# AE612FA0E5597BS0_CM55_HP_View register map
Vendor: Alif Semiconductor; Series: E6; File version: 1.0
CPU: CM55 r1p0, selectable endian, MPU, FPU, double-precision FPU, DSP, VTOR, 8 interrupt priority bits, 1 SAU regions
Registers are 32-bit, read-write, reset 0x0 unless marked. A register's access mark holds for its fields unless they carry their own. Offsets are from the block's base; [hi:lo] are bit positions; {n}, {i} and the like mark numbered series.

## LPSPI0
Base 0x43000000
Same registers: LPSPI1 0x43004000
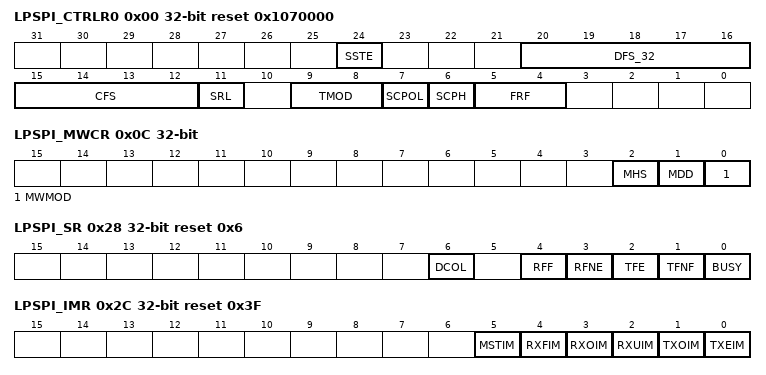
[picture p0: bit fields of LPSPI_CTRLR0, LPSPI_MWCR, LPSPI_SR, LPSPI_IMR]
0x00 LPSPI_CTRLR0 reset 0x1070000 — Control Register 0
  [24] SSTE — Slave Select Toggle Enable. While operating in LPSPI mode with clock phase (SCPH) set to 0x0, this bit controls the behavior of the slave select line between data frames.
    0=The slave select line will stay low and LPSPI_SCLK will run continuously for the duration of the transfer; 1=The slave select line will toggle between consecutive data frames, with the serial clock (LPSPI_SCLK) being held to its default value while the slave select line is high
  [20:16] DFS_32 — Data Frame Size in 32-bit transfer mode. Selects the data frame size in 32-bit transfer mode. When the data frame size is programmed to be less than 32 bits, the receive data is automatically right-justified by the receive logic, with the upper bits of the receive FIFO zero-padded. User must right-justify transmit data before writing into the transmit FIFO. The transmit logic ignores the upper unused bits when transmitting the data.
    {v}={v+1:02}-bit serial data transfer (v=3..31)
  [15:12] CFS — Control Frame Size. Selects the length of the control word for the Microwire frame format.
    {v}={v+1:02}-bit Control Word (v=0..15)
  [11] SRL — Shift Register Loop. Used for testing purposes only. When internally active, connects the transmit shift register output to the receive shift register input. Can be used in both serial slave and serial master mode.
    0=Normal Mode Operation; 1=Test Mode Operation
  [9:8] TMOD — Transfer Mode. Selects the mode of transfer for serial communication. This field does not affect the transfer duplicity. Only indicates whether the receive or transmit data are valid. In Transmit Only mode, data received from the external device is not valid and is not stored in the receive FIFO memory; it is overwritten on the next transfer. In Receive Only mode, transmitted data are not valid. After the first write to the transmit FIFO, the same word is retransmitted for the duration of the transfer. In Transmit and Receive mode, both transmit and receive data are valid. The transfer continues until the transmit FIFO is empty. Data received from the external device are stored into the receive FIFO memory, where it can be accessed by the host processor. In EEPROM-read mode, receive data is not valid while control data is being transmitted. When all control data is sent to the EEPROM, receive data becomes valid and transmit data becomes invalid. All data in the transmit FIFO is considered control data in this mode. This transfer mode is only valid when the LPSPI is programmed as master device.
    0=Transmit and Receive; 1=Transmit Only mode; 2=Receive Only mode; 3=EEPROM Read mode
  [7] SCPOL — Serial Clock Polarity. Valid when the Frame Format (FRF) bit is set to Motorola SPI. Used to select the polarity of the inactive serial clock, which is held inactive when the LPSPI master is not actively transferring data on the serial bus.
    0=Inactive state of serial clock is low; 1=Inactive state of serial clock is high
  [6] SCPH — Serial Clock Phase. Valid when the FRF bit is set to Motorola SPI. The serial clock phase selects the relationship of the serial clock with the slave select signal. When SCPH = 0, data are captured on the first edge of the serial clock. When SCPH = 1, the serial clock starts toggling one cycle after the slave select line is activated, and data are captured on the second edge of the serial clock.
    0=Serial clock toggles in middle of first bit; 1=Serial clock toggles at start of first bit
  [5:4] FRF — Frame Format. Selects which serial protocol transfers the data.
    0=Motorola SPI frame format; 1=Texas Instruments SSP frame format; 2=National Semiconductors Microwire frame format
0x04 LPSPI_CTRLR1 — Control Register 1
  [15:0] NDF — Number of Data Frames. When the LPSPI_CTRLR0[TMOD] = 0x2 or LPSPI_CTRLR0[TMOD] = 0x3, this bit field sets the number of data frames to be continuously received by the LPSPI. The LPSPI continues to receive serial data until the number of data frames received is equal to this register value plus 1, which enables the user to receive up to 64KB of data in a continuous transfer. When the SPI is programmed as a serial slave, the transfer continues for as long as the slave is selected. Therefore, this bit field serves no purpose and is not present when the SPI is programmed as a serial slave.
0x08 LPSPI_ENR — LPSPI Enable Register
  [0] SPI_EN — LPSPI Enable. Enables and disables all LPSPI operations. When disabled, all serial transfers are halted immediately. Transmit and receive FIFO buffers are cleared when the device is disabled. It is impossible to program some of the LPSPI control registers when enabled. When disabled, the LPSPI sleep output is set (after delay) to inform the system that it is safe to remove the LPSPI_CLK, thus saving power consumption in the system.
    0=Disables LPSPI; 1=Enables LPSPI
0x0C LPSPI_MWCR — Microwire Control Register
  [2] MHS — Microwire Handshaking. Relevant only when the LPSPI is programmed as a serial master device. When configured as a serial slave, this bit has no functionality. Used to enable and disable the busy/ready handshaking interface for the Microwire protocol. When enabled, the LPSPI checks for a READY status from the target slave, after the transfer of the last data/control bit, before clearing the BUSY status in the LPSPI_SR[BUSY] bit.
    0=Handshaking interface is disabled; 1=Handshaking interface is enabled
  [1] MDD — Microwire Control. Defines the direction of the data word when the Microwire serial protocol is used. When this bit is set to 0, the data word is received by the LPSPI module from the external serial device. When this bit is set to 1, the data word is transmitted from the LPSPI module to the external serial device.
    0=LPSPI receives data; 1=LPSPI transmits data
  [0] MWMOD — Microwire Transfer Mode. Defines whether the Microwire transfer is sequential or non-sequential. When sequential mode is used, only one control word is needed to transmit or receive a block of data words. When non-sequential mode is used, there must be a control word for each data word that is transmitted or received.
    0=Non-Sequential Transfer; 1=Sequential Transfer
0x10 LPSPI_SER reset 0x1 — Slave Enable Register
  [3:0] SER — Slave Select Enable Flag. Each bit in this bit field corresponds to a slave select line from the LPSPI master. When a bit in this bit field is set to 0x1, the corresponding slave select line from the master is activated when a serial transfer begins. It should be noted that setting or clearing bits in this bit field have no effect on the corresponding slave select outputs until a transfer is started. Before beginning a transfer, user should enable the bit in this field that corresponds to the slave device with which the master wants to communicate. When not operating in broadcast mode, only one bit in this field should be set.
    0=Not Selected; 1=Selected
0x14 LPSPI_BAUDR — Baud Rate Select Register
  [15:0] SCKDV — LPSPI Clock Divider. This field contains the MSB 15 bits of the 16-bit LPSPI_CLK divider value. The LSB for LPSPI_CLK divider is always set to 0 and is unaffected by a write operation, which ensures the divider is always set to an even value. If this field is set to all 0s, the serial output clock (LPSPI_SCLK) is disabled. The frequency of the LPSPI_SCLK is derived from the following equation: FLPSPI_SCLK = FLPSPI_CLK/SCKDV Where SCKDV is any even value between 2 and 65534. For example, for FLPSPI_CLK = 3.6864 MHz and SCKDV = 1b'1: SCKDV = 2 and FLPSPI_SCLK= 3.6864/2 = 1.8432 MHz. For more information, see Section SPI Clock Ratios.
0x18 LPSPI_TXFTLR — Transmit FIFO Threshold Level Register
  [3:0] TFT — Transmit FIFO Threshold. Controls the level of entries (or below) at which the transmit FIFO controller triggers an interrupt. The FIFO depth is 16. If the value in this bit field is set greater than or equal to the depth of the FIFO, this bit field is not written and retains its current value. When the number of transmit FIFO entries is less than or equal to this value, the transmit FIFO empty interrupt is triggered.
0x1C LPSPI_RXFTLR — Receive FIFO Threshold Level Register
  [3:0] RFT — Receive FIFO Threshold. Controls the level of entries (or above) at which the receive FIFO controller triggers an interrupt. The FIFO depth is 16. If the value in this bit field is set greater than the depth of the FIFO, this bit field is not written and retains its current value. When the number of receive FIFO entries is greater than or equal to this value + 1, the receive FIFO full interrupt is triggered.
0x20 LPSPI_TXFLR ro — Transmit FIFO Level Register
  [4:0] TXTFL — Transmit FIFO Level. Contains the number of valid data entries in the transmit FIFO.
0x24 LPSPI_RXFLR ro — Receive FIFO Level Register
  [4:0] RXTFL — Receive FIFO Level. Contains the number of valid data entries in the receive FIFO.
0x28 LPSPI_SR ro reset 0x6 — Status Register
  [6] DCOL — Data Collision Error. Relevant only when the LPSPI is programmed as a master device. This bit is set if slave select input is asserted by other master, when the LPSPI master is in the middle of the transfer. This informs the processor that the last data transfer was halted before completion. This bit is cleared when read.
    0=No Error; 1=Transmit Data Collision Error
  [4] RFF — Receive FIFO Full. When the receive FIFO is completely full, this bit is set. When the receive FIFO contains one or more empty location, this bit is cleared.
    0=Receive FIFO is not full; 1=Receive FIFO is full
  [3] RFNE — Receive FIFO Not Empty. Set when the receive FIFO contains one or more entries and is cleared when the receive FIFO is empty. This bit can be polled by software to completely empty the receive FIFO.
    0=Receive FIFO is empty; 1=Receive FIFO is not empty
  [2] TFE — Transmit FIFO Empty. When the transmit FIFO is completely empty, this bit is set. When the transmit FIFO contains one or more valid entries, this bit is cleared. This bit field does not request an interrupt.
    0=Transmit FIFO is not empty; 1=Transmit FIFO is empty
  [1] TFNF — Transmit FIFO Not Full. Set when the transmit FIFO contains one or more empty locations, and is cleared when the FIFO is full.
    0=Transmit FIFO is full; 1=Transmit FIFO is not full
  [0] BUSY — LPSPI Busy Flag. When set, indicates that a serial transfer is in progress; when cleared indicates that the LPSPI is idle or disabled.
    0=LPSPI is idle or disabled; 1=LPSPI is actively transferring data
0x2C LPSPI_IMR reset 0x3F — Interrupt Mask Register
  [5] MSTIM — Multi-Master Contention Interrupt Mask.
    0=Multi-Master Contention interrupt is masked; 1=Multi-Master Contention interrupt is not masked
  [4] RXFIM — Receive FIFO Full Interrupt Mask.
    0=Receive FIFO Full interrupt is masked; 1=Receive FIFO Full interrupt is not masked
  [3] RXOIM — Receive FIFO Overflow Interrupt Mask.
    0=Receive FIFO Overflow interrupt is masked; 1=Receive FIFO Overflow interrupt is not masked
  [2] RXUIM — Receive FIFO Underflow Interrupt Mask.
    0=Receive FIFO Underflow interrupt is masked; 1=Receive FIFO Underflow interrupt is not masked
  [1] TXOIM — Transmit FIFO Overflow Interrupt Mask.
    0=Transmit FIFO Overflow interrupt is masked; 1=Transmit FIFO Overflow interrupt is not masked
  [0] TXEIM — Transmit FIFO Empty Interrupt Mask.
    0=Transmit FIFO Empty interrupt is masked; 1=Transmit FIFO Empty interrupt is not masked
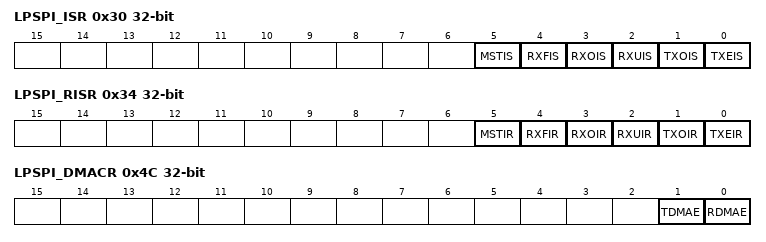
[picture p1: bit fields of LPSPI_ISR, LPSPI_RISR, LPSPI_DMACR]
0x30 LPSPI_ISR ro — Interrupt Status Register
  [5] MSTIS — Multi-Master Contention Interrupt Status. Note: This bit is not present if the SPI is programmed as a serial slave device.
    0=Multi-Master Contention interrupt is not active after masking; 1=Multi-Master Contention interrupt is active after masking
  [4] RXFIS — Receive FIFO Full Interrupt Status.
    0=Receive FIFO Full interrupt is not active after masking; 1=Receive FIFO Full interrupt is active after masking
  [3] RXOIS — Receive FIFO Overflow Interrupt Status.
    0=Receive FIFO Overflow interrupt is not active after masking; 1=Receive FIFO Overflow interrupt is active after masking
  [2] RXUIS — Receive FIFO Underflow Interrupt Status.
    0=Receive FIFO Underflow interrupt is not active after masking; 1=Receive FIFO Underflow interrupt is active after masking
  [1] TXOIS — Transmit FIFO Overflow Interrupt Status.
    0=Transmit FIFO Overflow interrupt is not active after masking; 1=Transmit FIFO Overflow interrupt is active after masking
  [0] TXEIS — Transmit FIFO Empty Interrupt Status.
    0=Transmit FIFO Empty interrupt is not active after masking; 1=Transmit FIFO Empty interrupt is active after masking
0x34 LPSPI_RISR ro — Raw Interrupt Status Register
  [5] MSTIR — Multi-Master Contention Raw Interrupt Status. This bit field is not functional if the LPSPI is programmed as a serial slave device.
    0=Multi-Master Contention interrupt is not active prior masking; 1=Multi-Master Contention interrupt is active prior to masking
  [4] RXFIR — Receive FIFO Full Raw Interrupt Status.
    0=Receive FIFO Full interrupt is not active prior masking; 1=Receive FIFO Full interrupt is active prior to masking
  [3] RXOIR — Receive FIFO Overflow Raw Interrupt Status.
    0=Receive FIFO Overflow interrupt is not active prior masking; 1=Receive FIFO Overflow interrupt is active prior to masking
  [2] RXUIR — Receive FIFO Underflow Raw Interrupt Status.
    0=Receive FIFO Underflow interrupt is not active prior masking; 1=Receive FIFO Underflow interrupt is active prior to masking
  [1] TXOIR — Transmit FIFO Overflow Raw Interrupt Status.
    0=Transmit FIFO Overflow interrupt is not active prior masking; 1=Transmit FIFO Overflow interrupt is active prior to masking
  [0] TXEIR — Transmit FIFO Empty Raw Interrupt Status.
    0=Transmit FIFO Empty interrupt is not active prior masking; 1=Transmit FIFO Empty interrupt is active prior to masking
0x38 LPSPI_TXOICR ro — Transmit FIFO Overflow Interrupt Clear Register
  [0] TXOICR — Clear Transmit FIFO Overflow Interrupt. This bit reflects the status of the interrupt. A read from this bit clears the Transmit FIFO Overflow interrupt; writing has no effect.
0x3C LPSPI_RXOICR ro — Receive FIFO Overflow Interrupt Clear Register
  [0] RXOICR — Clear Receive FIFO Overflow Interrupt. This bit reflects the status of the interrupt. A read from this bit clears the Receive FIFO Overflow interrupt; writing has no effect.
0x40 LPSPI_RXUICR ro — Receive FIFO Underflow Interrupt Clear Register
  [0] RXUICR — Clear Receive FIFO Underflow Interrupt. This bit reflects the status of the interrupt. A read from this bit clears the Receive FIFO Underflow interrupt; writing has no effect.
0x44 LPSPI_MSTICR ro — Multi-Master Interrupt Clear Register
  [0] MSTICR — Clear Multi-Master Contention Interrupt. This bit reflects the status of the interrupt. A read from this bit clears the Multi-Master Contention interrupt; writing has no effect.
0x48 LPSPI_ICR ro — Interrupt Clear Register
  [0] ICR — Clear Interrupts. This bit is set if any of the interrupts below are active. A read clears the Transmit FIFO Overflow, Receive FIFO Underflow, Receive FIFO Overflow, and Multi-Master Contention interrupts. Writing to this bit has no effect.
0x4C LPSPI_DMACR — DMA Control Register
  [1] TDMAE — Transmit DMA Enable. This bit enables/disables the transmit FIFO DMA channel.
    0=Transmit DMA disabled; 1=Transmit DMA enabled
  [0] RDMAE — Receive DMA Enable. This bit enables/disables the receive FIFO DMA channel.
    0=Receive DMA disabled; 1=Receive DMA enabled
0x50 LPSPI_DMATDLR — DMA Transmit Data Level Register
  [3:0] DMATDL — Transmit Data Level. This bit field controls the level at which a DMA request is made by the transmit logic. It is equal to the watermark level; that is, the transmit DMA request signal is generated when the number of valid data entries in the transmit FIFO is equal to or below this bit field value, and the LPSPI_DMACR[TDMAE] = 0x1.
0x54 LPSPI_DMARDLR — DMA Receive Data Level Register
  [3:0] DMARDL — Receive Data Level. This bit field controls the level at which a DMA request is made by the receive logic. The watermark level is equal to DMARDL + 1; that is, receive DMA request is generated when the number of valid data entries in the receive FIFO is equal to or above this bit field value + 1, and LPSPI_DMACR[RDMAE] = 0x1.
0x58 LPSPI_IDR ro reset 0xC7C5C3C1 — Identification Register
  [31:0] IDCODE — Identification code
0x5C LPSPI_VERSION_ID ro reset 0x3430332A — Version ID Register
  [31:0] SPI_COMP_VERSION — Component version
{0x60+4i} LPSPI_DR[{i}] (i=0..35) — LPSPI Data Register (n)
  [31:0] DR — Data Register (n). When writing to this register, the user must right-justify the data. Read data are automatically right-justified. Read = Receive FIFO buffer Write = Transmit FIFO buffer
